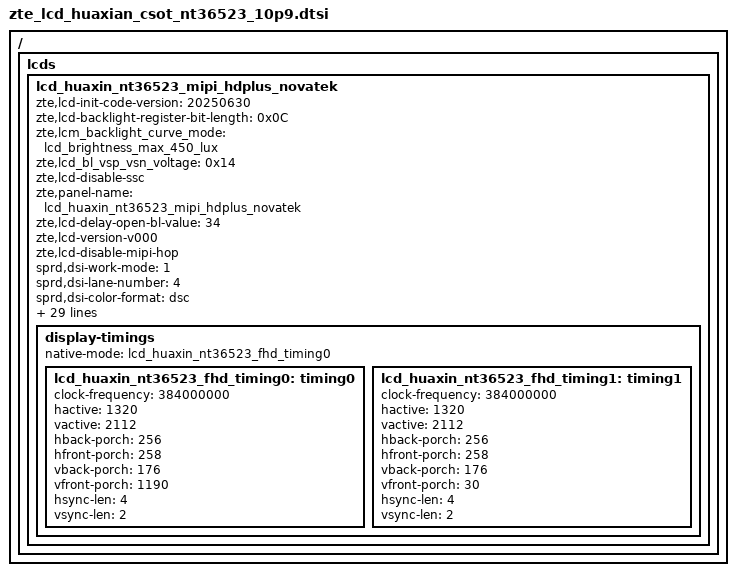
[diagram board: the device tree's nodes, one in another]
/ {
	fragment {
		target-path = "/";
		__overlay__ {
			lcds {
				lcd_huaxin_nt36523_mipi_hdplus_novatek: lcd_huaxin_nt36523_mipi_hdplus_novatek {
					zte,lcd-init-code-version = "20250630";

					zte,lcd-backlight-register-bit-length = <0x0C>;
					zte,lcm_backlight_curve_mode = "lcd_brightness_max_450_lux";
					zte,lcd_bl_vsp_vsn_voltage = <0x14>;
					zte,lcd-disable-ssc;
					zte,panel-name = "lcd_huaxin_nt36523_mipi_hdplus_novatek";
					zte,lcd-delay-open-bl-value = <34>;
					zte,lcd-version-v000;
					zte,lcd-disable-mipi-hop;

					sprd,dsi-work-mode = <1>;
					sprd,dsi-lane-number = <4>;
					sprd,dsi-color-format = "dsc";
					sprd,dpi-clk-div = <0>;
					//sprd,video-lp-cmd-enable = <1>;
					//sprd,video-lp-en-mode = <3>;
					sprd,dsi-non-continuous-clock;
					sprd,hporch-lp-disable = <1>;
					sprd,vrr-enabled;
					sprd,vrr-max-layers = <3>;
					sprd,slice-width = <660>;
					sprd,slice-height = <24>;
					sprd,output-bpc = <8>;
					sprd,dsc-enable = <1>;
					sprd,dual-dsi-enable = <0>;

					sprd,phy-bit-clock = <1152000>;
					sprd,phy-escape-clock = <20000>;/* kHz */

					sprd,width-mm = <14680>;
					sprd,height-mm = <23488>;

					sprd,esd-check-enable = <1>;/* 0:close , 1:open */
					sprd,esd-check-mode = <1>;/* 0:REG ,1:TE  */
					sprd,esd-check-period = <2000>;
					sprd,esd-check-register = <0x0A>;
					sprd,esd-check-value = <0x9C>;

					sprd,dphy-taget-val = <5>;

					sprd,reset-on-sequence = <0 10>, <1 10>, <0 10>, <1 20>;
					sprd,reset-off-sequence = <1 20>;

					sprd,use-gen-write;
					sprd,initial-command = [
39 00 00 02 ff 20
39 00 00 02 fb 01
39 00 00 02 07 7d
39 00 00 02 08 55
39 00 00 02 0d 63
39 00 00 02 0e 9b
39 00 00 02 0f 73
39 00 00 02 58 43
39 00 00 02 65 ff
39 00 00 02 69 dd
39 00 00 02 6d ff
39 00 00 02 6e 00
39 00 00 02 94 40
39 00 00 02 95 F5
39 00 00 02 96 13
39 00 00 02 9D 0A
39 00 00 02 9E 1E
39 00 00 02 ff 24
39 00 00 02 fb 01
39 00 00 02 00 11
39 00 00 02 01 11
39 00 00 02 02 10
39 00 00 02 03 10
39 00 00 02 04 0f
39 00 00 02 05 0f
39 00 00 02 06 0e
39 00 00 02 07 0e
39 00 00 02 08 0d
39 00 00 02 09 0d
39 00 00 02 0a 0c
39 00 00 02 0b 0c
39 00 00 02 0c 05
39 00 00 02 0d 05
39 00 00 02 0e 26
39 00 00 02 0f 26
39 00 00 02 10 1d
39 00 00 02 11 1d
39 00 00 02 12 1c
39 00 00 02 13 1c
39 00 00 02 14 08
39 00 00 02 15 08
39 00 00 02 16 11
39 00 00 02 17 11
39 00 00 02 18 10
39 00 00 02 19 10
39 00 00 02 1a 0f
39 00 00 02 1b 0f
39 00 00 02 1c 0e
39 00 00 02 1d 0e
39 00 00 02 1e 0d
39 00 00 02 1f 0d
39 00 00 02 20 0c
39 00 00 02 21 0c
39 00 00 02 22 04
39 00 00 02 23 04
39 00 00 02 24 26
39 00 00 02 25 26
39 00 00 02 26 1d
39 00 00 02 27 1d
39 00 00 02 28 1c
39 00 00 02 29 1c
39 00 00 02 2a 08
39 00 00 02 2b 08
39 00 00 02 2f 08
39 00 00 02 30 07
39 00 00 02 37 cc
39 00 00 02 3a 09
39 00 00 02 3b 62
39 00 00 02 3d 82
39 00 00 02 3f 15
39 00 00 02 47 a8
39 00 00 02 4a 09
39 00 00 02 4b 62
39 00 00 02 4c 81
39 00 00 02 50 87
39 00 00 03 55 85 03
39 00 00 02 59 60
39 00 00 02 5a 4f
39 00 00 02 5b 66
39 00 00 02 5c 93
39 00 00 02 5d 00
39 00 00 03 5e 00 06
39 00 00 02 60 a5
39 00 00 02 61 40
39 00 00 02 63 80
39 00 00 02 7a 04
39 00 00 02 7b 40
39 00 00 02 7e 20
39 00 00 02 7f b4
39 00 00 02 92 6b
39 00 00 03 94 b2 00
39 00 00 02 96 80
39 00 00 02 99 40
39 00 00 0d b6 05 00 05 00 00 00 05 05 05 05 05 05
39 00 00 02 bb 80
39 00 00 06 bc 00 00 43 20 00
39 00 00 04 c2 c7 00 08
39 00 00 02 db 0f
39 00 00 02 dc 58
39 00 00 02 df 0f
39 00 00 02 e0 58
39 00 00 02 e1 0f
39 00 00 02 e2 58
39 00 00 02 e3 0f
39 00 00 02 e4 58
39 00 00 02 e5 0f
39 00 00 02 e6 58
39 00 00 02 e9 0f
39 00 00 02 ea 58
39 00 00 02 eb 0f
39 00 00 02 ec 80
39 00 00 02 ee 58
39 00 00 02 ef 0f
39 00 00 02 f0 58
39 00 00 02 ff 25
39 00 00 02 fb 01
39 00 00 02 05 04
39 00 00 02 13 02
39 00 00 02 14 05
39 00 00 02 15 02
39 00 00 02 16 b1
39 00 00 02 1b 55
39 00 00 02 1f 4f
39 00 00 02 20 66
39 00 00 02 26 4f
39 00 00 02 27 66
39 00 00 02 33 4f
39 00 00 02 34 66
39 00 00 02 3f 00
39 00 00 02 40 00
39 00 00 02 44 09
39 00 00 02 45 62
39 00 00 02 46 09
39 00 00 02 47 62
39 00 00 02 48 4f
39 00 00 02 49 66
39 00 00 02 50 4f
39 00 00 02 51 66
39 00 00 02 5b 00
39 00 00 02 5d 09
39 00 00 02 5e 62
39 00 00 02 5f 09
39 00 00 02 60 62
39 00 00 02 61 4f
39 00 00 02 62 66
39 00 00 02 68 00
39 00 00 02 c5 17
39 00 00 02 c6 11
39 00 00 02 db 01
39 00 00 02 dc 97
39 00 00 02 dd 02
39 00 00 02 de 1f
39 00 00 02 ff 26
39 00 00 02 fb 01
39 00 00 02 00 81
39 00 00 02 04 64
39 00 00 02 06 41
39 00 00 02 0a f5
39 00 00 02 0c 04
39 00 00 02 0d 00
39 00 00 02 0f 09
39 00 00 02 11 00
39 00 00 02 12 51
39 00 00 02 13 a8
39 00 00 02 14 a6
39 00 00 02 16 91
39 00 00 02 19 20
39 00 00 02 1a d1
39 00 00 02 1b 1d
39 00 00 02 1c c6
39 00 00 02 1e 6b
39 00 00 02 1f 6b
39 00 00 02 24 02
39 00 00 02 25 6b
39 00 00 02 26 26
39 00 00 02 2a 1e
39 00 00 02 2b b0
39 00 00 02 2f 06
39 00 00 02 30 6b
39 00 00 02 32 6b
39 00 00 02 33 32
39 00 00 02 34 33
39 00 00 02 35 66
39 00 00 02 36 66
39 00 00 02 37 66
39 00 00 02 38 06
39 00 00 02 39 02
39 00 00 02 3a 6b
39 00 00 02 3b 06
39 00 00 02 40 76
39 00 00 02 41 76
39 00 00 02 42 76
39 00 00 02 43 02
39 00 00 02 44 76
39 00 00 02 45 06
39 00 00 02 46 76
39 00 00 02 48 76
39 00 00 02 49 02
39 00 00 02 4a 76
39 00 00 02 4b 06
39 00 00 02 4d 09
39 00 00 02 4e 6b
39 00 00 02 4f 09
39 00 00 02 50 6b
39 00 00 02 51 4f
39 00 00 02 52 4F
39 00 00 02 56 4f
39 00 00 02 58 4F
39 00 00 02 5b 4f
39 00 00 02 5c 4F
39 00 00 02 60 4f
39 00 00 02 61 4F
39 00 00 02 64 4f
39 00 00 02 65 4F
39 00 00 02 69 4f
39 00 00 02 6a 4F
39 00 00 02 6e 09
39 00 00 02 6f 6b
39 00 00 02 70 09
39 00 00 02 71 6b
39 00 00 02 72 4f
39 00 00 02 73 4F
39 00 00 02 80 ff
39 00 00 02 81 ff
39 00 00 05 82 00 62 62 62
39 00 00 02 8b 64
39 00 00 02 8c 0e
39 00 00 02 8d 08
39 00 00 02 8f 00
39 00 00 02 91 00
39 00 00 02 92 50
39 00 00 02 93 7f
39 00 00 02 94 91
39 00 00 02 96 10
39 00 00 02 99 1b
39 00 00 02 9a 06
39 00 00 02 9b 19
39 00 00 02 9c 22
39 00 00 02 9d 1a
39 00 00 02 9e 0c
39 00 00 02 a7 08
39 00 00 03 a9 ae 01
39 00 00 03 aa b4 01
39 00 00 03 ab ba 01
39 00 00 03 ac c0 01
39 00 00 03 ad c6 01
39 00 00 03 ae ad 01
39 00 00 03 af b3 01
39 00 00 03 b0 b9 01
39 00 00 03 b1 bf 01
39 00 00 03 b2 c5 01
39 00 00 03 b3 ac 01
39 00 00 03 b4 b2 01
39 00 00 03 b5 b8 01
39 00 00 03 b6 be 01
39 00 00 03 b7 c4 01
39 00 00 03 b8 ab 01
39 00 00 03 b9 b1 01
39 00 00 03 ba b7 01
39 00 00 03 bb bd 01
39 00 00 03 bc c3 01
39 00 00 03 bd aa 01
39 00 00 03 be b0 01
39 00 00 03 bf b6 01
39 00 00 03 c0 bc 01
39 00 00 03 c1 c2 01
39 00 00 03 c2 a9 01
39 00 00 03 c3 af 01
39 00 00 03 c4 b5 01
39 00 00 03 c5 bb 01
39 00 00 02 c8 00
39 00 00 02 c9 1e
39 00 00 02 ca 6e
39 00 00 02 cb 9e
39 00 00 03 cd 33 6b
39 00 00 03 ce 31 6b
39 00 00 04 cf 01 00 2a
39 00 00 02 d2 8f
39 00 00 02 d6 85
39 00 00 02 d7 8b
39 00 00 02 d8 91
39 00 00 02 d9 97
39 00 00 02 da 9d
39 00 00 02 db 84
39 00 00 02 dc 8a
39 00 00 02 dd 90
39 00 00 02 de 96
39 00 00 02 df 9c
39 00 00 02 e0 83
39 00 00 02 e1 89
39 00 00 02 e2 8f
39 00 00 02 e3 95
39 00 00 02 e4 9b
39 00 00 02 e5 82
39 00 00 02 e6 88
39 00 00 02 e7 8e
39 00 00 02 e8 94
39 00 00 02 e9 9a
39 00 00 02 ea 81
39 00 00 02 eb 87
39 00 00 02 ec 8d
39 00 00 02 ed 93
39 00 00 02 ee 99
39 00 00 02 ef 80
39 00 00 02 f0 86
39 00 00 02 f1 8c
39 00 00 02 f2 92

39 00 00 02 ff 27
39 00 00 02 fb 01
39 00 00 02 13 06
39 00 00 02 58 80
39 00 00 02 59 00
39 00 00 02 5a 00
39 00 00 02 5b ca
39 00 00 02 5c 01
39 00 00 02 5d 4b
39 00 00 02 5e 00
39 00 00 02 5f 08
39 00 00 02 60 fc
39 00 00 02 61 83
39 00 00 02 62 84
39 00 00 02 63 00
39 00 00 02 64 00
39 00 00 02 65 82
39 00 00 02 66 84
39 00 00 02 67 00
39 00 00 02 68 00
39 00 00 02 78 80
39 00 00 02 79 00
39 00 00 02 7a 00
39 00 00 02 7b ae
39 00 00 02 7c 00
39 00 00 02 7d 00
39 00 00 02 7e 00
39 00 00 02 7f 00
39 00 00 02 80 00
39 00 00 02 81 00
39 00 00 02 82 00
39 00 00 02 83 00
39 00 00 02 84 00
39 00 00 02 85 00
39 00 00 02 86 00
39 00 00 02 87 00
39 00 00 02 88 00
39 00 00 02 de 43
39 00 00 02 df 02
39 00 00 02 ff 2a
39 00 00 02 fb 01
39 00 00 02 22 0f
39 00 00 02 24 00
39 00 00 02 25 6b
39 00 00 02 27 00
39 00 00 02 28 1e
39 00 00 02 29 00
39 00 00 02 2a 1e
39 00 00 02 2b 00
39 00 00 02 2d 1e
39 00 00 02 2f 00
39 00 00 02 30 76
39 00 00 02 32 00
39 00 00 02 33 1e
39 00 00 02 34 00
39 00 00 02 35 1e
39 00 00 02 36 00
39 00 00 02 37 1e
39 00 00 02 64 16
39 00 00 02 67 16
39 00 00 02 6a 16
39 00 00 02 70 16
39 00 00 02 7f 16
39 00 00 02 88 16
39 00 00 02 99 95
39 00 00 02 9a 06
39 00 00 02 9b 00
39 00 00 02 a2 3f
39 00 00 02 a4 c3
39 00 00 0a b9 18 00 a4 00 10 94 db 70 40
39 00 00 03 bc 33 03
39 00 00 02 e8 00
39 00 00 02 f4 95
39 00 00 02 f5 06
39 00 00 02 f6 00
39 00 00 02 ff f0
39 00 00 02 fb 01
39 00 00 02 24 02
39 00 00 02 ff 27 /* esd */
39 00 00 02 fb 01
39 00 00 02 d0 03
39 00 00 02 d1 55
39 00 00 02 d2 30
39 00 00 02 ff 10
39 00 00 02 fb 01
39 00 00 07 3b 03 b2 1e 04 04 00
39 00 00 02 90 03
39 00 00 11 91 89 28 00 18 C2 00 02 4A 02 88 00 09 04 2D 03 78
39 00 00 03 92 10 f0
39 00 00 02 b2 80
39 00 00 02 b3 11
39 00 00 02 35 00
05 64 00 01 11
05 14 00 01 29
					];

					sprd,sleep-in-command = [
						39 05 00 02 28 00
						39 78 00 02 10 00
						];
					sprd,sleep-out-command = [
						05 78 00 01 11
						05 14 00 01 29
						];
					display-timings {
						native-mode = <&lcd_huaxin_nt36523_fhd_timing0>;
						lcd_huaxin_nt36523_fhd_timing0: timing0 {
							clock-frequency = <384000000>;
							hactive = <1320>;
							vactive = <2112>;
							hback-porch = <256>;
							hfront-porch = <258>;
							vback-porch = <176>;
							vfront-porch = <1190>;
							hsync-len = <4>;
							vsync-len = <2>;
						};
						lcd_huaxin_nt36523_fhd_timing1: timing1 {
							clock-frequency = <384000000>;
							hactive = <1320>;
							vactive = <2112>;
							hback-porch = <256>;
							hfront-porch = <258>;
							vback-porch = <176>;
							vfront-porch = <30>;
							hsync-len = <4>;
							vsync-len = <2>;
						};
					};
				};
			};
		};
	};
};
